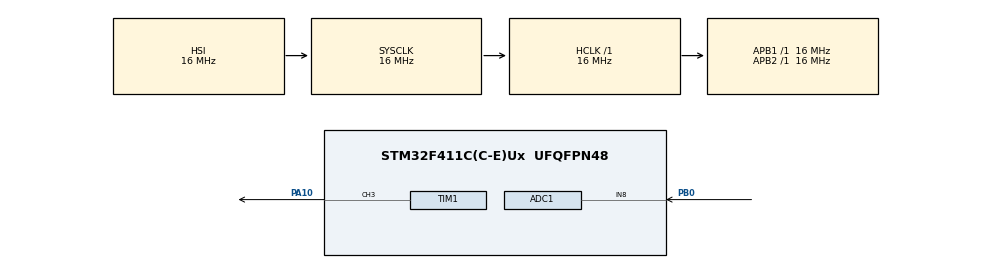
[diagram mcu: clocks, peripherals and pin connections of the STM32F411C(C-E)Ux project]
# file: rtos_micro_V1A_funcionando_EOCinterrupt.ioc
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ADC1.Channel-0\#ChannelRegularConversion=ADC_CHANNEL_8
ADC1.NbrOfConversionFlag=1
ADC1.Rank-0\#ChannelRegularConversion=1
ADC1.SamplingTime-0\#ChannelRegularConversion=ADC_SAMPLETIME_3CYCLES
ADC1.master=1
Dma.Request0=TIM1_UP
Dma.TIM1_UP.0.Direction=DMA_MEMORY_TO_PERIPH
Dma.TIM1_UP.0.FIFOMode=DMA_FIFOMODE_ENABLE
Dma.TIM1_UP.0.FIFOThreshold=DMA_FIFO_THRESHOLD_1QUARTERFULL
Dma.TIM1_UP.0.Instance=DMA2_Stream5
Dma.TIM1_UP.0.MemBurst=DMA_MBURST_SINGLE
Dma.TIM1_UP.0.MemDataAlignment=DMA_MDATAALIGN_HALFWORD
Dma.TIM1_UP.0.MemInc=DMA_MINC_ENABLE
Dma.TIM1_UP.0.Mode=DMA_NORMAL
Dma.TIM1_UP.0.PeriphBurst=DMA_PBURST_SINGLE
Dma.TIM1_UP.0.PeriphDataAlignment=DMA_PDATAALIGN_HALFWORD
Dma.TIM1_UP.0.PeriphInc=DMA_PINC_DISABLE
Dma.TIM1_UP.0.Priority=DMA_PRIORITY_LOW
FREERTOS.BinarySemaphores01=adcSemaphore,Dynamic,NULL,Available
FREERTOS.Tasks01=vuMeterTask,32,512,VuMeterTask,Default,NULL,Dynamic,NULL,NULL
Mcu.Family=STM32F4
Mcu.Name=STM32F411C(C-E)Ux
Mcu.Package=UFQFPN48
NVIC.ADC_IRQn=true\:5\:0\:false\:false\:true\:true\:true\:true\:true
NVIC.DMA2_Stream5_IRQn=true\:5\:0\:false\:false\:true\:true\:false\:true\:true
NVIC.PriorityGroup=NVIC_PRIORITYGROUP_4
NVIC.TIM3_IRQn=true\:15\:0\:false\:false\:true\:false\:false\:true\:true
NVIC.TimeBase=TIM3_IRQn
NVIC.TimeBaseIP=TIM3
PA10.Signal=S_TIM1_CH3
PA13.Mode=Serial_Wire
PA13.Signal=SYS_JTMS-SWDIO
PA14.Mode=Serial_Wire
PA14.Signal=SYS_JTCK-SWCLK
PB0.Signal=SharedAnalog_PB0
PH0\ -\ OSC_IN.Mode=HSE-External-Oscillator
PH0\ -\ OSC_IN.Signal=RCC_OSC_IN
PH1\ -\ OSC_OUT.Mode=HSE-External-Oscillator
PH1\ -\ OSC_OUT.Signal=RCC_OSC_OUT
ProjectManager.HeapSize=0x200
ProjectManager.StackSize=0x400
ProjectManager.TargetToolchain=STM32CubeIDE
RCC.48MHZClocksFreq_Value=75000000
RCC.AHBFreq_Value=16000000
RCC.APB1Freq_Value=16000000
RCC.APB1TimFreq_Value=16000000
RCC.APB2Freq_Value=16000000
RCC.APB2TimFreq_Value=16000000
RCC.CortexFreq_Value=16000000
RCC.HCLKFreq_Value=16000000
RCC.HSE_VALUE=25000000
RCC.HSI_VALUE=16000000
RCC.LSE_VALUE=32768
RCC.PLLSourceVirtual=RCC_PLLSOURCE_HSE
RCC.SYSCLKFreq_VALUE=16000000
RCC.VCOOutputFreq_Value=300000000
SH.S_TIM1_CH3.0=TIM1_CH3,PWM Generation3 CH3
SH.SharedAnalog_PB0.0=GPIO_Analog
SH.SharedAnalog_PB0.1=ADC1_IN8,IN8
TIM1.AutoReloadPreload=TIM_AUTORELOAD_PRELOAD_ENABLE
TIM1.Channel-PWM\ Generation3\ CH3=TIM_CHANNEL_3
TIM1.Period=9
TIM1.Prescaler=1
VP_FREERTOS_VS_CMSIS_V2.Mode=CMSIS_V2
VP_SYS_VS_tim3.Mode=TIM3
board=custom

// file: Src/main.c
/* USER CODE BEGIN Header */
/**
  ******************************************************************************
  * @file           : main.c
  * @brief          : Main program body
  ******************************************************************************
  * @attention
  *
  * Copyright (c) 2026 STMicroelectronics.
  * All rights reserved.
  *
  * This software is licensed under terms that can be found in the LICENSE file
  * in the root directory of this software component.
  * If no LICENSE file comes with this software, it is provided AS-IS.
  *
  ******************************************************************************
  */
/* USER CODE END Header */
#include "main.h"
#include "cmsis_os.h"
#include "adc.h"
#include "dma.h"
#include "tim.h"
#include "gpio.h"

void SystemClock_Config(void);
void MX_FREERTOS_Init(void);

int main(void)
{

  /* MCU Configuration--------------------------------------------------------*/

  /* Reset of all peripherals, Initializes the Flash interface and the Systick. */
  HAL_Init();

  /* Configure the system clock */
  SystemClock_Config();

  /* Initialize all configured peripherals */
  MX_GPIO_Init();
  MX_DMA_Init();
  MX_ADC1_Init();
  MX_TIM1_Init();
  /* USER CODE BEGIN 2 */
  HAL_TIM_PWM_Start(&htim1, TIM_CHANNEL_3);
  ws2812_color_init(25);
  ws2812_pwm_init();
  /* USER CODE END 2 */

  /* Init scheduler */
  osKernelInitialize();  /* Call init function for freertos objects (in cmsis_os2.c) */
  MX_FREERTOS_Init();

  /* Start scheduler */
  osKernelStart();

  /* We should never get here as control is now taken by the scheduler */

  /* Infinite loop */
  while (1)
  {

  }
}

void SystemClock_Config(void)
{
  RCC_OscInitTypeDef RCC_OscInitStruct = {0};
  RCC_ClkInitTypeDef RCC_ClkInitStruct = {0};

  /** Configure the main internal regulator output voltage
  */
  __HAL_RCC_PWR_CLK_ENABLE();
  __HAL_PWR_VOLTAGESCALING_CONFIG(PWR_REGULATOR_VOLTAGE_SCALE1);

  /** Initializes the RCC Oscillators according to the specified parameters
  * in the RCC_OscInitTypeDef structure.
  */
  RCC_OscInitStruct.OscillatorType = RCC_OSCILLATORTYPE_HSI;
  RCC_OscInitStruct.HSIState = RCC_HSI_ON;
  RCC_OscInitStruct.HSICalibrationValue = RCC_HSICALIBRATION_DEFAULT;
  RCC_OscInitStruct.PLL.PLLState = RCC_PLL_NONE;
  if (HAL_RCC_OscConfig(&RCC_OscInitStruct) != HAL_OK)
  {
    Error_Handler();
  }

  /** Initializes the CPU, AHB and APB buses clocks
  */
  RCC_ClkInitStruct.ClockType = RCC_CLOCKTYPE_HCLK|RCC_CLOCKTYPE_SYSCLK
                              |RCC_CLOCKTYPE_PCLK1|RCC_CLOCKTYPE_PCLK2;
  RCC_ClkInitStruct.SYSCLKSource = RCC_SYSCLKSOURCE_HSI;
  RCC_ClkInitStruct.AHBCLKDivider = RCC_SYSCLK_DIV1;
  RCC_ClkInitStruct.APB1CLKDivider = RCC_HCLK_DIV1;
  RCC_ClkInitStruct.APB2CLKDivider = RCC_HCLK_DIV1;

  if (HAL_RCC_ClockConfig(&RCC_ClkInitStruct, FLASH_LATENCY_0) != HAL_OK)
  {
    Error_Handler();
  }
}

void HAL_TIM_PeriodElapsedCallback(TIM_HandleTypeDef *htim)
{
  if (htim->Instance == TIM3)
  {
    HAL_IncTick();
  }
}

void Error_Handler(void)
{
  __disable_irq();
  while (1)
  {
  }
}

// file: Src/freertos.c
/* USER CODE BEGIN Header */
/**
    ******************************************************************************
  * @file    :freertos.c
  * @brief   :Implementação do VU Meter utilizando FreeRTOS e WS2812
  * @author  :Pedro Henrique Guerra
  * @date    : 20/4/2026
  * @details
  * Este módulo implementa um sistema de medição de nível de sinal (VU Meter)
  * utilizando uma matriz de LEDs endereçáveis WS2812
  * baseado em FreeRTOS.
  *
  * Arquitetura do sistema:
  *
  * - Task principal (VuMeterTask)
  * - ADC operando em modo interrupção
  * - Sincronização via semáforo
  * - Processamento logarítmico do sinal
  * - Atualização de matriz WS2812 via PWM + DMA
  *
  * Fluxo de execução:
  *
  * ADC -> Interrupção -> Semáforo -> Task -> Processamento -> Atualização LED
  ******************************************************************************
  * @attention
  *
  * Copyright (c) 2026 STMicroelectronics.
  * All rights reserved.
  *
  * This software is licensed under terms that can be found in the LICENSE file
  * in the root directory of this software component.
  * If no LICENSE file comes with this software, it is provided AS-IS.
  *
  ******************************************************************************
  */
/* USER CODE END Header */

#include "FreeRTOS.h"
#include "task.h"
#include "main.h"
#include "cmsis_os.h"

/* USER CODE BEGIN Includes */
#include "adc.h"
#include <math.h>
#include "dma.h"
#include "tim.h"

/* USER CODE END Includes */

/* USER CODE BEGIN PD */
/**
 * @def ADC_OFFSET
 * @brief Offset aplicado ao sinal analógico.
 *
 * Utilizado para remover o valor DC do sinal de entrada.
 * Em aplicações de áudio, o sinal costuma estar centrado em Vref/2.
 */

#define ADC_OFFSET 2048.0f

/**
 * @def NEOPIXEL_COLS
 * @brief Número de colunas da matriz de LEDs.
 */

#define NEOPIXEL_COLS 5

/**
 * @def NEOPIXEL_ROWS
 * @brief Número de linhas da matriz de LEDs.
 */
#define NEOPIXEL_ROWS 5

/**
 * @def NEOPIXEL_LEDS
 * @brief Número total de LEDs da matriz.
 */
#define NEOPIXEL_LEDS (NEOPIXEL_COLS * NEOPIXEL_ROWS)
/* USER CODE END PD */

/* USER CODE BEGIN Variables */
/**
 * @brief Último valor convertido pelo ADC.
 */

volatile uint16_t adc_value;
/**
* @brief last_value Último número de LEDs acesos.
*/

uint8_t last_value = 0;

/* USER CODE END Variables */
/* Definitions for vuMeterTask */
osThreadId_t vuMeterTaskHandle;
const osThreadAttr_t vuMeterTask_attributes = {
  .name = "vuMeterTask",
  .stack_size = 512 * 4,
  .priority = (osPriority_t) osPriorityAboveNormal,
};
/* Definitions for adcSemaphore */
/**
 * @brief Semáforo de sincronização ADC → Task
 *
 * @details
 * Liberado na ISR do ADC e consumido pela VuMeterTask.
 */
osSemaphoreId_t adcSemaphoreHandle;
const osSemaphoreAttr_t adcSemaphore_attributes = {
  .name = "adcSemaphore"
};

/* USER CODE BEGIN FunctionPrototypes */
void HAL_ADC_ConvCpltCallback(ADC_HandleTypeDef* hadc);
uint8_t vu_meter(uint16_t adc_value, uint8_t last_value);
void color_gradient(float percentage,uint8_t *r, uint8_t *g, uint8_t *b);
void set_pixel(uint8_t x, uint8_t y, uint8_t r, uint8_t g, uint8_t b);
void update_display(void);
/* USER CODE END FunctionPrototypes */

void VuMeterTask(void *argument);

void MX_FREERTOS_Init(void); /* (MISRA C 2004 rule 8.1) */

void MX_FREERTOS_Init(void) {

  /* Create the semaphores(s) */
  /* creation of adcSemaphore */
  adcSemaphoreHandle = osSemaphoreNew(1, 0, &adcSemaphore_attributes);

  /* Create the thread(s) */
  /* creation of vuMeterTask */
  vuMeterTaskHandle = osThreadNew(VuMeterTask, NULL, &vuMeterTask_attributes);

}

/* USER CODE BEGIN Header_VuMeterTask */
/**
  * @brief Task responsável pelo processamento do VU Meter.
  *
  * @details
  * Fluxo da task:
  *
  * 1. Inicia conversão ADC
  * 2. Aguarda sinalização via semáforo
  * 3. Processa valor do ADC
  * 4. Atualiza matriz de LEDs
  * 5. Aguarda pequeno intervalo
  *
  * Sincronização:
  * - Utiliza semáforo liberado pela ISR do ADC
  *
  * @param argument Parâmetro não utilizado
  */
/* USER CODE END Header_VuMeterTask */
void VuMeterTask(void *argument)
{
  /* USER CODE BEGIN VuMeterTask */
  /* Infinite loop */

    while(1)
    {
    	HAL_ADC_Start_IT(&hadc1);

        osSemaphoreAcquire(adcSemaphoreHandle, osWaitForever);

        last_value = vu_meter(adc_value, last_value);

        osDelay(10);

    }
  /* USER CODE END VuMeterTask */
}

/* USER CODE BEGIN Application */
/**
 * @brief Callback de término de conversão do ADC.
 *
 * @param hadc Ponteiro para o handle do ADC.
 *
 * @details
 * Executado em contexto de interrupção.
 *
 * Responsabilidades:
 * - Capturar valor convertido
 * - Liberar semáforo para a task
 *
 * @note
 * NÃO realizar processamento pesado nesta função.
 */

void HAL_ADC_ConvCpltCallback(ADC_HandleTypeDef* hadc)
{
    if(hadc->Instance == ADC1)
    {
        adc_value = HAL_ADC_GetValue(&hadc1);

        osSemaphoreRelease(adcSemaphoreHandle);
    }
}

/**
 * @brief Calcula o nível do VU Meter e atualiza a matriz de LEDs.
 *
 * @param adc_value Valor bruto lido do ADC.
 * @param last_value Último número de LEDs acesos.
 *
 * @return Número atual de LEDs acesos.
 *
 * @details
 * Esta função executa o processamento principal do firmware:
 *
 * 1. Remove o offset do sinal
 * 2. Amplifica o sinal para melhorar sensibilidade
 * 3. Normaliza o valor para a faixa 0–1
 * 4. Aplica uma escala logarítmica para simular resposta de VU Meter
 * 5. Calcula quantos LEDs devem ser acesos
 * 6. Atualiza a matriz com gradiente de cores
 *
 * A escala logarítmica é utilizada para melhorar a percepção visual
 * de sinais de baixa amplitude.
 */

uint8_t vu_meter(uint16_t adc_value, uint8_t last_value)
{
    float volume;
    float volume_ratio;
    uint8_t num_leds_lit;

    volume = (float)adc_value - ADC_OFFSET;

    if (volume < 0)
        volume = 0;

    volume *= 3.0f;

    volume_ratio = volume / 4096.0f;

    num_leds_lit = (uint8_t)(
        NEOPIXEL_LEDS * log10f(1.0f + 9.0f * volume_ratio)
    );

    if(num_leds_lit != last_value)
    {

        for(uint8_t i=0;i<NEOPIXEL_LEDS;i++)
            ws2812_set_pixel(i,0,0,0);

        for(uint8_t i=0;i<num_leds_lit;i++)
        {

            uint8_t x = i % NEOPIXEL_COLS;
            uint8_t y = i / NEOPIXEL_COLS;

            uint8_t r,g,b;

            color_gradient((float)i/(NEOPIXEL_LEDS-1),&r,&g,&b);

            set_pixel(x,y,r,g,b);
        }

        update_display();
    }

    return num_leds_lit;
}
    /**
     * @brief Calcula a cor correspondente a uma posição no gradiente.
     *
     * @param percentage Valor normalizado entre 0 e 1.
     * @param r Ponteiro para o componente vermelho.
     * @param g Ponteiro para o componente verde.
     * @param b Ponteiro para o componente azul.
     *
     * @details
     * Gera um gradiente de cor utilizado no VU Meter:
     *
     * azul → verde → vermelho
     *
     * O gradiente permite identificar visualmente diferentes
     * níveis de intensidade do sinal.
     */

    void color_gradient(float percentage,
                               uint8_t *r,
                               uint8_t *g,
                               uint8_t *b)
    {
        if (percentage < 0.5f) {

            *r = 0;
            *g = (uint8_t)(510.0f * percentage);
            *b = 255 - *g;

        } else {

            *g = 255 - (uint8_t)(510.0f * (percentage - 0.5f));
            *r = 255 - *g;
            *b = 0;

        }
    }

    /**
     * @brief Define a cor de um LED na matriz.
     *
     * @param x Coordenada horizontal do LED
     * @param y Coordenada vertical do LED
     * @param r Intensidade do componente vermelho
     * @param g Intensidade do componente verde
     * @param b Intensidade do componente azul
     *
     * @details
     * Converte as coordenadas (x,y) em um índice linear utilizado
     * pela biblioteca WS2812.
     *
     * O cálculo considera a orientação da matriz de LEDs.
     */

    void set_pixel(uint8_t x, uint8_t y,
                          uint8_t r, uint8_t g, uint8_t b)
    {
        uint16_t index = (NEOPIXEL_ROWS - 1 - y) * NEOPIXEL_COLS + x;

        ws2812_set_pixel(index, r, g, b);
    }

    /**
     * @brief Atualiza o estado da matriz de LEDs.
     *
     * @details
     * Envia os dados armazenados no buffer de LEDs para a cadeia
     * WS2812 utilizando PWM + DMA.
     */

    void update_display(void)
    {
        ws2812_pwm_show();
    }
/* USER CODE END Application */
